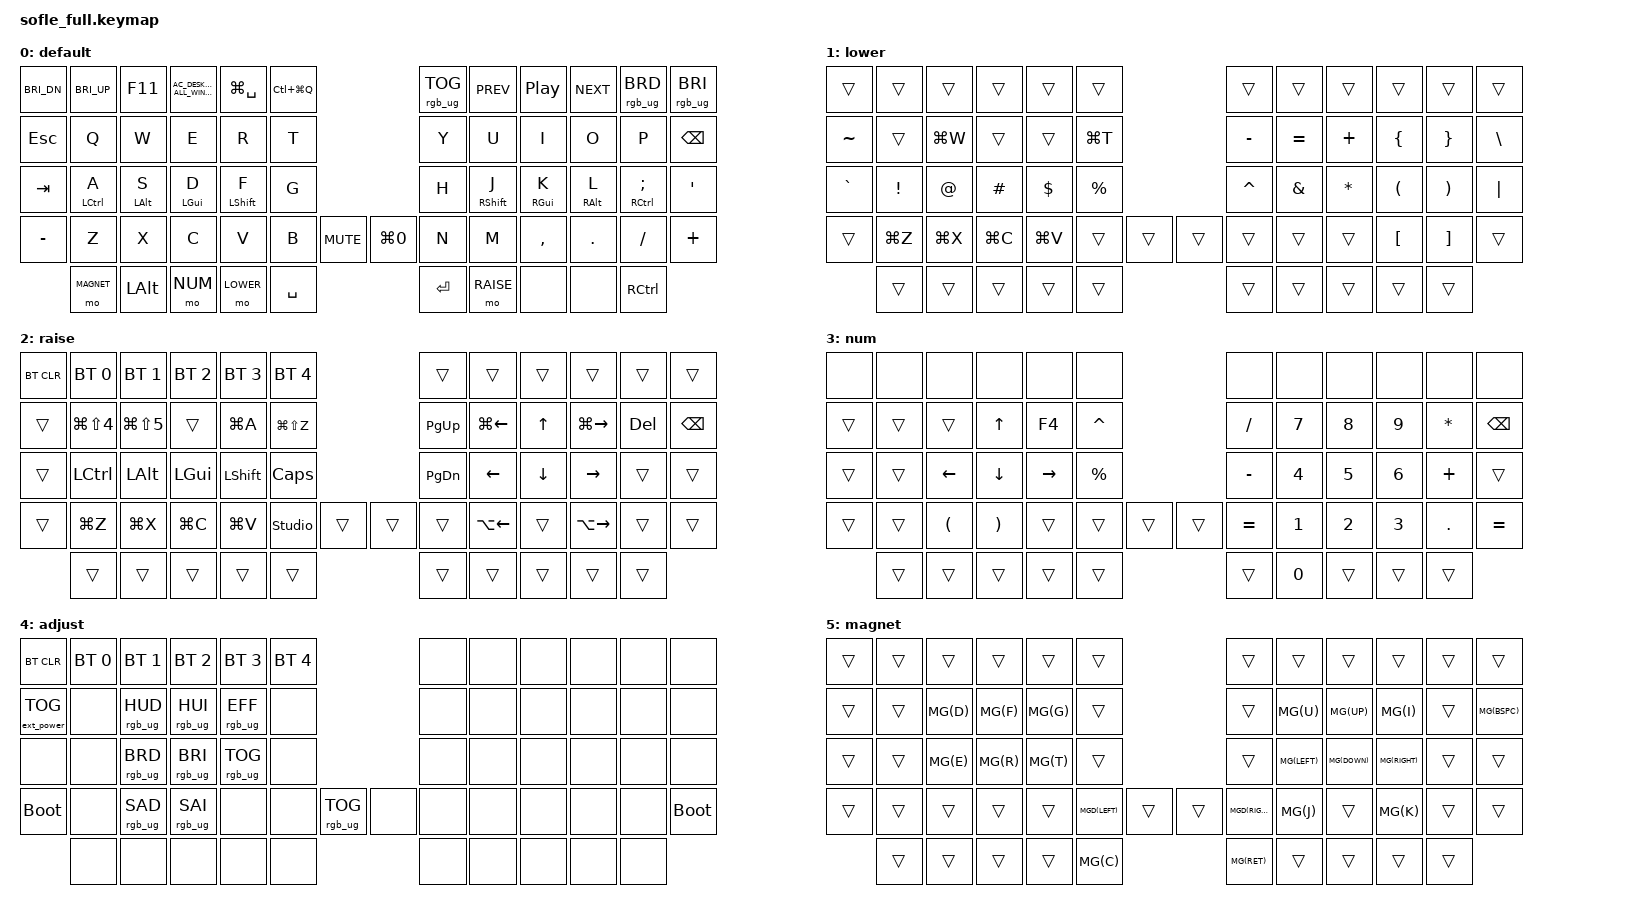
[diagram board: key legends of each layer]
/*
* Copyright (c) 2020 The ZMK Contributors
*
* SPDX-License-Identifier: MIT
*/

#include <behaviors.dtsi>
#include <dt-bindings/zmk/keys.h>
#include <dt-bindings/zmk/bt.h>
#include <dt-bindings/zmk/rgb.h>
#include <dt-bindings/zmk/ext_power.h>

#define BASE 0
#define LOWER 1
#define RAISE 2
#define NUM 3
#define ADJUST 4
#define MAGNET 5

// Magnet (macOS window manager) shortcuts are all Ctrl+Option+<key>
#define MG(k) &kp LC(LA(k))
#define MGD(k) &kp LC(LA(LG(k)))

/ {

  behaviors {
    // Home row mods: tap = letter, hold = modifier. Positional: the hold only triggers when the next key
    // is on the opposite hand (or a bottom-row/thumb key), so same-hand rolls still type letters.
    // Key positions: 5 rows, rows 0-2 are 12 keys, row 3 is 14 (incl. 2 encoder keys), row 4 is 10.
    hml: homerow_mod_left {
      compatible = "zmk,behavior-hold-tap";
      #binding-cells = <2>;
      flavor = "balanced";
      tapping-term-ms = <280>;
      quick-tap-ms = <175>;
      require-prior-idle-ms = <150>;
      hold-trigger-on-release;
      hold-trigger-key-positions = <6 7 8 9 10 11 18 19 20 21 22 23 30 31 32 33 34 35 44 45 46 47 48 49 50 51 52 53 54 55 56 57 58 59>;
      bindings = <&kp>, <&kp>;
    };

    hmr: homerow_mod_right {
      compatible = "zmk,behavior-hold-tap";
      #binding-cells = <2>;
      flavor = "balanced";
      tapping-term-ms = <280>;
      quick-tap-ms = <175>;
      require-prior-idle-ms = <150>;
      hold-trigger-on-release;
      hold-trigger-key-positions = <0 1 2 3 4 5 12 13 14 15 16 17 24 25 26 27 28 29 36 37 38 39 40 41 50 51 52 53 54 55 56 57 58 59>;
      bindings = <&kp>, <&kp>;
    };

    // Encoder behavior: clockwise = brighter, counter-clockwise = dimmer
    // (this board's encoders report reversed, same as the volume bindings use VOL_DN first)
    rgb_enc: rgb_encoder {
      compatible = "zmk,behavior-sensor-rotate";
      #sensor-binding-cells = <0>;
      bindings = <&rgb_ug RGB_BRD>, <&rgb_ug RGB_BRI>;
    };
  };

  // Activate ADJUST layer by pressing raise and lower
  conditional_layers {
    compatible = "zmk,conditional-layers";
    adjust_layer {
      if-layers = <LOWER RAISE>;
      then-layer = <ADJUST>;
    };
  };

  keymap {
    compatible = "zmk,keymap";

    default_layer {
      display-name = "default";
      // Hold W/T/Z/X/C/V/B = Cmd+key (close, new tab, undo, cut, copy, paste, redo); tap types the letter
      // Hold the left-thumb MAGNET key = MAGNET layer (no tap action). Hold the thumb NUM key = NUM layer
      // DESK = Show Desktop (F11), MISSN = Mission Control, SPOT = Spotlight (Cmd+Space), LOCK = Ctrl+Cmd+Q, LED = RGB underglow
      // -----------------------------------------------------------------------------------------------------------------
      // |  BRI- |  BRI+ |  DESK | MISSN |  SPOT |  LOCK |               |  LED  |  PREV |  PLAY |  NEXT |  LED- |  LED+ |
      // |  ESC  |   Q   |   W   |   E   |   R   |   T   |               |   Y   |   U   |   I   |   O   |   P   | BKSPC |
      // |  TAB  | A/CTL | S/OPT | D/CMD | F/SHFT|   G   |               |   H   | J/SHFT| K/CMD | L/OPT | ;/CTL |   '   |
      // |   -   |   Z   |   X   |   C   |   V   |   B   |  MUTE | ZOOM0 |   N   |   M   |   ,   |   .   |   /   |   +   |
      //         |MAGNET |  OPT  |  NUM  | LOWER | SPACE |               | ENTER | RAISE |       |       |  CTRL |
      bindings = <
        &kp C_BRI_DN &kp C_BRI_UP    &kp F11         &kp C_AC_DESKTOP_SHOW_ALL_WINDOWS &kp LG(SPACE)   &kp LC(LG(Q))                               &rgb_ug RGB_TOG &kp C_PREV   &kp C_PP    &kp C_NEXT  &rgb_ug RGB_BRD &rgb_ug RGB_BRI
        &kp ESC      &kp Q           &kp W           &kp E                             &kp R           &kp T                                       &kp Y           &kp U        &kp I       &kp O       &kp P           &kp BSPC
        &kp TAB      &hml LCTRL A    &hml LALT S     &hml LGUI D                       &hml LSHFT F    &kp G                                       &kp H           &hmr RSHFT J &hmr RGUI K &hmr RALT L &hmr RCTRL SEMI &kp SQT
        &kp MINUS    &kp Z           &kp X           &kp C                             &kp V           &kp B                &kp C_MUTE &kp LG(N0)  &kp N           &kp M        &kp COMMA   &kp DOT     &kp FSLH        &kp PLUS
                     &mo MAGNET      &kp LALT        &mo NUM                           &mo LOWER       &kp SPACE                                   &kp RET         &mo RAISE    &none       &none       &kp RCTRL
      >;

      sensor-bindings = <&inc_dec_kp C_VOL_DN C_VOL_UP &inc_dec_kp LG(MINUS) LG(EQUAL)>;
    };

    lower_layer {
      display-name = "lower";
      // Symbols only. Brackets pair up around the parens: { } above, [ ] below. - = + and \ sit on the right
      // -----------------------------------------------------------------------------------------------------------------
      // |       |       |       |       |       |       |               |       |       |       |       |       |       |
      // |   ~   |       | CLOSE |       |       |  TAB  |               |   -   |   =   |   +   |   {   |   }   |   \   |
      // |   `   |   !   |   @   |   #   |   $   |   %   |               |   ^   |   &   |   *   |   (   |   )   |   |   |
      // |       | UNDO  |  CUT  | COPY  | PASTE |       |       |       |       |       |       |   [   |   ]   |       |
      //         |       |       |       |       |       |               |       |       |       |       |       |
      bindings = <
        &trans    &trans   &trans &trans   &trans   &trans                    &trans    &trans    &trans    &trans   &trans   &trans
        &kp TILDE &trans   &kp LG(W) &trans &trans   &kp LG(T)                  &kp MINUS &kp EQUAL &kp PLUS  &kp LBRC &kp RBRC &kp BSLH
        &kp GRAVE &kp EXCL &kp AT &kp HASH &kp DLLR &kp PRCNT                 &kp CARET &kp AMPS  &kp ASTRK &kp LPAR &kp RPAR &kp PIPE
        &trans    &kp LG(Z) &kp LG(X) &kp LG(C) &kp LG(V) &trans     &trans &trans  &trans    &trans    &trans    &kp LBKT &kp RBKT &trans
                  &trans   &trans &trans   &trans   &trans                    &trans    &trans    &trans    &trans   &trans
      >;

      sensor-bindings = <&inc_dec_kp C_VOL_DN C_VOL_UP &inc_dec_kp LG(MINUS) LG(EQUAL)>;
    };

    raise_layer {
      display-name = "raise";
      // SCRN4/5 = Cmd+Shift+4 (selection) / Cmd+Shift+5 (more options); LINE< / LINE> = Cmd+Left / Cmd+Right; WORD< / WORD> = Opt+Left / Opt+Right
      // -----------------------------------------------------------------------------------------------------------------
      // | BTCLR |  BT1  |  BT2  |  BT3  |  BT4  |  BT5  |               |       |       |       |       |       |       |
      // |       | SCRN4 | SCRN5 |       | SELALL|  REDO |               |  PGUP | LINE< |   UP  | LINE> |  DEL  | BKSPC |
      // |       |  CTRL |  OPT  |  CMD  | SHIFT |  CAPS |               |  PGDN |  LEFT |  DOWN | RIGHT |       |       |
      // |       |  UNDO |  CUT  |  COPY | PASTE |  UNLK |       |       |       | WORD< |       | WORD> |       |       |
      //         |       |       |       |       |       |               |       |       |       |       |       |
      bindings = <
        &bt BT_CLR &bt BT_SEL 0 &bt BT_SEL 1 &bt BT_SEL 2 &bt BT_SEL 3 &bt BT_SEL 4                  &trans    &trans    &trans   &trans    &trans  &trans
        &trans     &kp LG(LS(N4)) &kp LG(LS(N5)) &trans &kp LG(A)  &kp LG(LS(Z))                &kp PG_UP &kp LG(LEFT) &kp UP &kp LG(RIGHT) &kp DEL &kp BSPC
        &trans     &kp LCTRL    &kp LALT     &kp LGUI     &kp LSHFT    &kp CLCK                      &kp PG_DN &kp LEFT  &kp DOWN &kp RIGHT &trans &trans
        &trans     &kp LG(Z)   &kp LG(X)    &kp LG(C)    &kp LG(V)    &studio_unlock        &trans  &trans  &trans    &kp LA(LEFT) &trans &kp LA(RIGHT) &trans  &trans
        &trans       &trans       &trans       &trans        &trans  &trans  &trans    &trans    &trans   &trans
      >;

      sensor-bindings = <&inc_dec_kp C_VOL_DN C_VOL_UP &inc_dec_kp LG(MINUS) LG(EQUAL)>;
    };

    num_layer {
      display-name = "num";
      // Momentary: hold the NUM key (left thumb on the base layer); release to leave
      // Left hand: E/S/D/F act as up/left/down/right arrows, F4 above the right arrow toggles Excel's $ reference lock
      // Digits sit one row below the letters they overlay, 0 on the RAISE thumb key. Left is lower, right is raise: - / shrink, + * grow
      // -----------------------------------------------------------------------------------------------------------------
      // |       |       |       |       |       |       |               |       |       |       |       |       |       |
      // |       |       |       |   UP  |   F4  |   ^   |               |   /   |   7   |   8   |   9   |   *   | BKSPC |
      // |       |       |  LEFT |  DOWN | RIGHT |   %   |               |   -   |   4   |   5   |   6   |   +   |       |
      // |       |       |   (   |   )   |       |       |       |       |   =   |   1   |   2   |   3   |   .   |   =   |
      //         |       |       |       |       |       |               |       |   0   |       |       |       |
      bindings = <
        &none  &none  &none    &none    &none     &none                     &none     &none  &none  &none  &none     &none
        &trans &trans &trans   &kp UP   &kp F4    &kp CARET                 &kp FSLH  &kp N7 &kp N8 &kp N9 &kp ASTRK &kp BSPC
        &trans &trans &kp LEFT &kp DOWN &kp RIGHT &kp PRCNT                 &kp MINUS &kp N4 &kp N5 &kp N6 &kp PLUS  &trans
        &trans &trans &kp LPAR &kp RPAR &trans    &trans     &trans &trans  &kp EQUAL &kp N1 &kp N2 &kp N3 &kp DOT   &kp EQUAL
               &trans &trans   &trans   &trans    &trans                    &trans    &kp N0 &trans &trans &trans
      >;
    };

    adjust_layer {
      display-name = "adjust";
      // BOOT = &bootloader: resets the half whose key you press into UF2 mode (no pin needed)
      // -----------------------------------------------------------------------------------------------------------------
      // | BTCLR |  BT1  |  BT2  |  BT3  |  BT4  |  BT5  |               |       |       |       |       |       |       |
      // | EXTPWR|       |RGB_HUD|RGB_HUI|RGB_EFF|       |               |       |       |       |       |       |       |
      // |       |       |RGB_BRD|RGB_BRI|RGB_TOG|       |               |       |       |       |       |       |       |
      // |  BOOT |       |RGB_SAD|RGB_SAI|       |       |RGB_TOG|       |       |       |       |       |       |  BOOT |
      //         |       |       |       |       |       |               |       |       |       |       |       |
      bindings = <
        &bt BT_CLR        &bt BT_SEL 0    &bt BT_SEL 1    &bt BT_SEL 2    &bt BT_SEL 3    &bt BT_SEL 4                            &none &none &none &none &none &none
        &ext_power EP_TOG &none           &rgb_ug RGB_HUD &rgb_ug RGB_HUI &rgb_ug RGB_EFF &none                                   &none &none &none &none &none &none
        &none             &none           &rgb_ug RGB_BRD &rgb_ug RGB_BRI &rgb_ug RGB_TOG &none                                   &none &none &none &none &none &none
        &bootloader       &none           &rgb_ug RGB_SAD &rgb_ug RGB_SAI &none           &none            &rgb_ug RGB_TOG &none  &none &none &none &none &none &bootloader
        &none           &none           &none           &none            &none           &none  &none &none &none &none
      >;

      // Left encoder: RGB brightness (click toggles RGB, see RGB_TOG above); right encoder unchanged
      sensor-bindings = <&rgb_enc &inc_dec_kp C_PREV C_NEXT>;
    };

    magnet_layer {
      display-name = "magnet";
      // Hold the left-thumb MAGNET key, then press one key below (Ctrl+Opt+key is sent). Letters match Magnet's own.
      // Halves use the same keys as the arrows on the RAISE layer (I = up, J/K/L = left/down/right)
      // -----------------------------------------------------------------------------------------------------------------
      // |       |       |       |       |       |       |               |       |       |       |       |       |       |
      // |       |       |  L1/3 |  C1/3 |  R1/3 |       |               |       |   TL  |  TOP  |   TR  |       | RSTOR |
      // |       |       |  L2/3 |  C2/3 |  R2/3 |       |               |       |  LEFT | BOTTOM| RIGHT |       |       |
      // |       |       |       |       |       | PREVD |       |       | NEXTD |   BL  |       |   BR  |       |       |
      //         |       |       |       |       | CENTER|               |  MAX  |       |       |       |       |
      bindings = <
        &trans &trans &trans &trans &trans &trans                    &trans     &trans   &trans   &trans    &trans &trans
        &trans &trans MG(D)  MG(F)  MG(G)  &trans                    &trans     MG(U)    MG(UP)   MG(I)     &trans MG(BSPC)
        &trans &trans MG(E)  MG(R)  MG(T)  &trans                    &trans     MG(LEFT) MG(DOWN) MG(RIGHT) &trans &trans
        &trans &trans &trans &trans &trans MGD(LEFT)  &trans &trans  MGD(RIGHT) MG(J)    &trans   MG(K)     &trans &trans
               &trans &trans &trans &trans MG(C)                     MG(RET)    &trans   &trans   &trans    &trans
      >;
    };
  };
};
